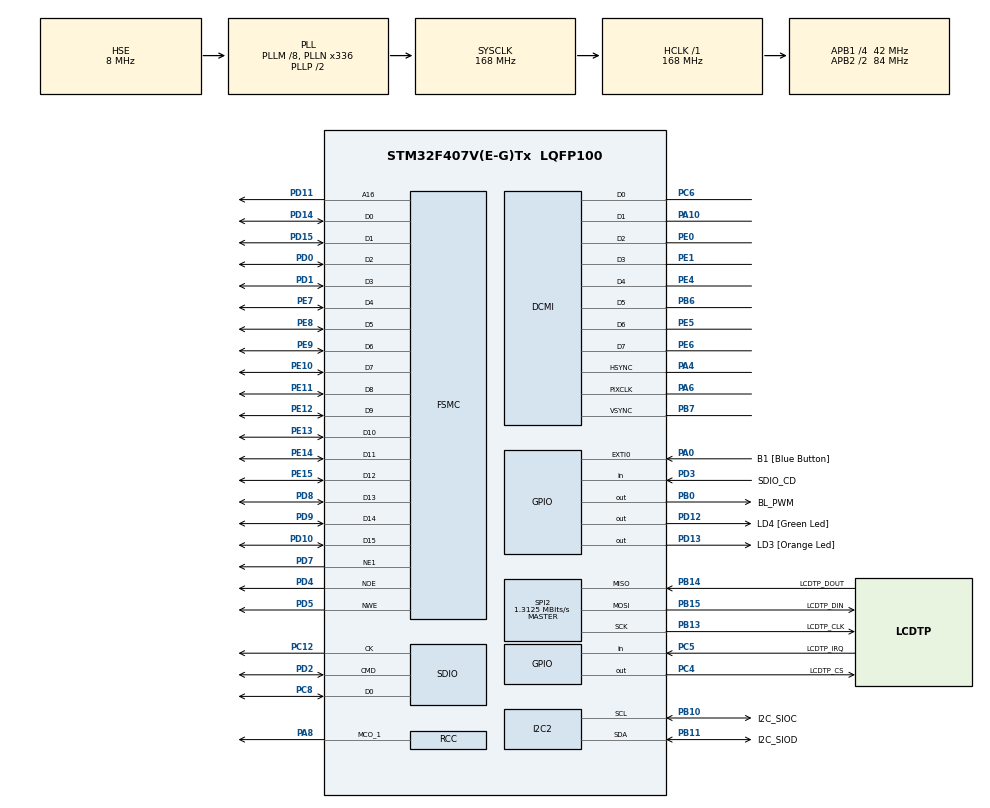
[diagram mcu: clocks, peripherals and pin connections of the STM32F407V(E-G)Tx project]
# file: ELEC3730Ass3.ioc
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DCMI.HSPolarity=DCMI_HSPOLARITY_HIGH
DCMI.VSPolarity=DCMI_VSPOLARITY_HIGH
Dma.DCMI.0.Direction=DMA_PERIPH_TO_MEMORY
Dma.DCMI.0.FIFOMode=DMA_FIFOMODE_ENABLE
Dma.DCMI.0.FIFOThreshold=DMA_FIFO_THRESHOLD_FULL
Dma.DCMI.0.Instance=DMA2_Stream1
Dma.DCMI.0.MemBurst=DMA_MBURST_SINGLE
Dma.DCMI.0.MemDataAlignment=DMA_MDATAALIGN_WORD
Dma.DCMI.0.MemInc=DMA_MINC_ENABLE
Dma.DCMI.0.Mode=DMA_CIRCULAR
Dma.DCMI.0.PeriphBurst=DMA_PBURST_SINGLE
Dma.DCMI.0.PeriphDataAlignment=DMA_PDATAALIGN_WORD
Dma.DCMI.0.PeriphInc=DMA_PINC_DISABLE
Dma.DCMI.0.Priority=DMA_PRIORITY_VERY_HIGH
Dma.MEMTOMEM.3.Direction=DMA_MEMORY_TO_MEMORY
Dma.MEMTOMEM.3.FIFOMode=DMA_FIFOMODE_ENABLE
Dma.MEMTOMEM.3.FIFOThreshold=DMA_FIFO_THRESHOLD_FULL
Dma.MEMTOMEM.3.Instance=DMA2_Stream0
Dma.MEMTOMEM.3.MemBurst=DMA_MBURST_SINGLE
Dma.MEMTOMEM.3.MemDataAlignment=DMA_MDATAALIGN_HALFWORD
Dma.MEMTOMEM.3.MemInc=DMA_MINC_DISABLE
Dma.MEMTOMEM.3.Mode=DMA_NORMAL
Dma.MEMTOMEM.3.PeriphBurst=DMA_PBURST_SINGLE
Dma.MEMTOMEM.3.PeriphDataAlignment=DMA_PDATAALIGN_HALFWORD
Dma.MEMTOMEM.3.PeriphInc=DMA_PINC_ENABLE
Dma.MEMTOMEM.3.Priority=DMA_PRIORITY_HIGH
Dma.Request0=DCMI
Dma.Request1=SDIO_RX
Dma.Request2=SDIO_TX
Dma.Request3=MEMTOMEM
Dma.SDIO_RX.1.Direction=DMA_PERIPH_TO_MEMORY
Dma.SDIO_RX.1.FIFOMode=DMA_FIFOMODE_ENABLE
Dma.SDIO_RX.1.FIFOThreshold=DMA_FIFO_THRESHOLD_FULL
Dma.SDIO_RX.1.Instance=DMA2_Stream3
Dma.SDIO_RX.1.MemBurst=DMA_MBURST_INC4
Dma.SDIO_RX.1.MemDataAlignment=DMA_MDATAALIGN_WORD
Dma.SDIO_RX.1.MemInc=DMA_MINC_ENABLE
Dma.SDIO_RX.1.Mode=DMA_PFCTRL
Dma.SDIO_RX.1.PeriphBurst=DMA_PBURST_INC4
Dma.SDIO_RX.1.PeriphDataAlignment=DMA_PDATAALIGN_WORD
Dma.SDIO_RX.1.PeriphInc=DMA_PINC_DISABLE
Dma.SDIO_RX.1.Priority=DMA_PRIORITY_VERY_HIGH
Dma.SDIO_TX.2.Direction=DMA_MEMORY_TO_PERIPH
Dma.SDIO_TX.2.FIFOMode=DMA_FIFOMODE_ENABLE
Dma.SDIO_TX.2.FIFOThreshold=DMA_FIFO_THRESHOLD_FULL
Dma.SDIO_TX.2.Instance=DMA2_Stream6
Dma.SDIO_TX.2.MemBurst=DMA_MBURST_INC4
Dma.SDIO_TX.2.MemDataAlignment=DMA_MDATAALIGN_WORD
Dma.SDIO_TX.2.MemInc=DMA_MINC_ENABLE
Dma.SDIO_TX.2.Mode=DMA_PFCTRL
Dma.SDIO_TX.2.PeriphBurst=DMA_PBURST_INC4
Dma.SDIO_TX.2.PeriphDataAlignment=DMA_PDATAALIGN_WORD
Dma.SDIO_TX.2.PeriphInc=DMA_PINC_DISABLE
Dma.SDIO_TX.2.Priority=DMA_PRIORITY_VERY_HIGH
FATFS.BSP.number=1
FATFS.USE_DMA_CODE_SD=1
FATFS._USE_LFN=2
FATFS0.BSP.STBoard=false
FATFS0.BSP.api=Unknown
FATFS0.BSP.instance=PD3
FATFS0.BSP.ip=GPIO
FATFS0.BSP.mode=Input
FATFS0.BSP.name=Detect_SDIO
FATFS0.BSP.solution=PD3
FREERTOS.BinarySemaphores01=startSem,Dynamic,NULL
FREERTOS.Mutexes01=lcdMutex,Dynamic,NULL;sdMutex,Dynamic,NULL
FREERTOS.Queues01=stateQueue,16,uint16_t,0,Dynamic,NULL,NULL;renderQueue,16,uint16_t,0,Dynamic,NULL,NULL;keypadQueue,4,uint16_t,0,Dynamic,NULL,NULL;fileSystemQueue,16,uint16_t,0,Dynamic,NULL,NULL
FREERTOS.Tasks01=defaultTask,0,128,StartDefaultTask,As weak,NULL,Dynamic,NULL,NULL;controlTask,0,128,StartControlTask,As weak,NULL,Dynamic,NULL,NULL;lcdTask,0,128,StartLCDTask,As weak,NULL,Dynamic,NULL,NULL;touchPanelTask,0,128,StartTouchPanelTask,As weak,NULL,Dynamic,NULL,NULL;keypadTask,0,128,StartKeypadTask,As weak,NULL,Dynamic,NULL,NULL;fileSystemTask,0,128,StartFileSystemTask,As weak,NULL,Dynamic,NULL,NULL;cameraTask,0,128,StartCameraTask,As weak,NULL,Dynamic,NULL,NULL
FREERTOS.Timers01=messageTimer,MessageTimerCallback,osTimerOnce,As weak,NULL,Dynamic,NULL
FREERTOS.configUSE_TIMERS=1
FSMC.AddressSetupTime1=4
FSMC.BusTurnAroundDuration1=0
FSMC.DataSetupTime1=40
Mcu.Family=STM32F4
Mcu.Name=STM32F407V(E-G)Tx
Mcu.Package=LQFP100
NVIC.DCMI_IRQn=true\:5\:0\:false\:false\:true\:true\:true\:true\:true
NVIC.DMA2_Stream1_IRQn=true\:5\:0\:false\:false\:true\:true\:false\:true\:true
NVIC.DMA2_Stream3_IRQn=true\:5\:0\:false\:false\:true\:true\:false\:true\:true
NVIC.DMA2_Stream6_IRQn=true\:5\:0\:false\:false\:true\:true\:false\:true\:true
NVIC.PriorityGroup=NVIC_PRIORITYGROUP_4
NVIC.SDIO_IRQn=true\:5\:0\:false\:false\:true\:true\:true\:true\:true
NVIC.SPI2_IRQn=true\:5\:0\:false\:false\:true\:true\:true\:true\:true
NVIC.TIM6_DAC_IRQn=true\:15\:0\:false\:false\:true\:false\:false\:true\:true
NVIC.TimeBase=TIM6_DAC_IRQn
NVIC.TimeBaseIP=TIM6
PA0-WKUP.GPIO_Label=B1 [Blue Button]
PA0-WKUP.GPIO_ModeDefaultEXTI=GPIO_MODE_EVT_RISING
PA0-WKUP.GPIO_PuPd=GPIO_NOPULL
PA0-WKUP.Signal=GPXTI0
PA10.Mode=Slave_8_bits_External_Synchro
PA10.Signal=DCMI_D1
PA4.Mode=Slave_8_bits_External_Synchro
PA4.Signal=DCMI_HSYNC
PA6.Mode=Slave_8_bits_External_Synchro
PA6.Signal=DCMI_PIXCLK
PA8.Mode=Clock-out-1
PA8.Signal=RCC_MCO_1
PB0.GPIO_Label=BL_PWM
PB0.Signal=GPIO_Output
PB10.GPIO_Label=I2C_SIOC
PB10.GPIO_Pu=GPIO_PULLUP
PB10.Mode=I2C
PB10.Signal=I2C2_SCL
PB11.GPIO_Label=I2C_SIOD
PB11.GPIO_Pu=GPIO_PULLUP
PB11.Mode=I2C
PB11.Signal=I2C2_SDA
PB13.GPIO_Label=LCDTP_CLK
PB13.Mode=Full_Duplex_Master
PB13.Signal=SPI2_SCK
PB14.GPIO_Label=LCDTP_DOUT
PB14.Mode=Full_Duplex_Master
PB14.Signal=SPI2_MISO
PB15.GPIO_Label=LCDTP_DIN
PB15.Mode=Full_Duplex_Master
PB15.Signal=SPI2_MOSI
PB6.Mode=Slave_8_bits_External_Synchro
PB6.Signal=DCMI_D5
PB7.Mode=Slave_8_bits_External_Synchro
PB7.Signal=DCMI_VSYNC
PC10.Signal=SDIO_D2
PC11.Signal=SDIO_D3
PC12.Mode=SD_1_bit
PC12.Signal=SDIO_CK
PC4.GPIO_Label=LCDTP_CS
PC4.GPIO_PuPd=GPIO_PULLDOWN
PC4.Signal=GPIO_Output
PC5.GPIO_Label=LCDTP_IRQ
PC5.Signal=GPIO_Input
PC6.Mode=Slave_8_bits_External_Synchro
PC6.Signal=DCMI_D0
PC8.Mode=SD_1_bit
PC8.Signal=SDIO_D0
PD0.Mode=16b-d1
PD0.Signal=FSMC_D2
PD1.Mode=16b-d1
PD1.Signal=FSMC_D3
PD10.Mode=16b-d1
PD10.Signal=FSMC_D15
PD11.Mode=A16_1
PD11.Signal=FSMC_A16
PD12.GPIO_Label=LD4 [Green Led]
PD12.GPIO_PuPd=GPIO_NOPULL
PD12.GPIO_Speed=GPIO_SPEED_FREQ_LOW
PD12.Signal=GPIO_Output
PD13.GPIO_Label=LD3 [Orange Led]
PD13.GPIO_PuPd=GPIO_NOPULL
PD13.GPIO_Speed=GPIO_SPEED_FREQ_LOW
PD13.Signal=GPIO_Output
PD14.Mode=16b-d1
PD14.Signal=FSMC_D0
PD15.Mode=16b-d1
PD15.Signal=FSMC_D1
PD2.Mode=SD_1_bit
PD2.Signal=SDIO_CMD
PD3.GPIO_Label=SDIO_CD
PD3.Signal=GPIO_Input
PD4.Mode=Lcd1
PD4.Signal=FSMC_NOE
PD5.Mode=Lcd1
PD5.Signal=FSMC_NWE
PD7.Mode=NorPsramChipSelect1_1
PD7.Signal=FSMC_NE1
PD8.Mode=16b-d1
PD8.Signal=FSMC_D13
PD9.Mode=16b-d1
PD9.Signal=FSMC_D14
PE0.Mode=Slave_8_bits_External_Synchro
PE0.Signal=DCMI_D2
PE1.Mode=Slave_8_bits_External_Synchro
PE1.Signal=DCMI_D3
PE10.Mode=16b-d1
PE10.Signal=FSMC_D7
PE11.Mode=16b-d1
PE11.Signal=FSMC_D8
PE12.Mode=16b-d1
PE12.Signal=FSMC_D9
PE13.Mode=16b-d1
PE13.Signal=FSMC_D10
PE14.Mode=16b-d1
PE14.Signal=FSMC_D11
PE15.Mode=16b-d1
PE15.Signal=FSMC_D12
PE4.Mode=Slave_8_bits_External_Synchro
PE4.Signal=DCMI_D4
PE5.Mode=Slave_8_bits_External_Synchro
PE5.Signal=DCMI_D6
PE6.Mode=Slave_8_bits_External_Synchro
PE6.Signal=DCMI_D7
PE7.Mode=16b-d1
PE7.Signal=FSMC_D4
PE8.Mode=16b-d1
PE8.Signal=FSMC_D5
PE9.Mode=16b-d1
PE9.Signal=FSMC_D6
PH0-OSC_IN.GPIO_Label=PH0-OSC_IN
PH0-OSC_IN.Mode=HSE-External-Oscillator
PH0-OSC_IN.Signal=RCC_OSC_IN
PH1-OSC_OUT.GPIO_Label=PH1-OSC_OUT
PH1-OSC_OUT.Mode=HSE-External-Oscillator
PH1-OSC_OUT.Signal=RCC_OSC_OUT
ProjectManager.HeapSize=0x200
ProjectManager.StackSize=0x400
ProjectManager.TargetToolchain=STM32CubeIDE
RCC.48MHZClocksFreq_Value=48000000
RCC.AHBFreq_Value=168000000
RCC.APB1CLKDivider=RCC_HCLK_DIV4
RCC.APB1Freq_Value=42000000
RCC.APB1TimFreq_Value=84000000
RCC.APB2CLKDivider=RCC_HCLK_DIV2
RCC.APB2Freq_Value=84000000
RCC.APB2TimFreq_Value=168000000
RCC.CortexFreq_Value=168000000
RCC.HCLKFreq_Value=168000000
RCC.HSE_VALUE=8000000
RCC.HSI_VALUE=16000000
RCC.LSE_VALUE=32768
RCC.PLLM=8
RCC.PLLN=336
RCC.PLLQ=7
RCC.PLLSourceVirtual=RCC_PLLSOURCE_HSE
RCC.SYSCLKFreq_VALUE=168000000
RCC.SYSCLKSource=RCC_SYSCLKSOURCE_PLLCLK
RCC.VCOOutputFreq_Value=336000000
SPI2.BaudRatePrescaler=SPI_BAUDRATEPRESCALER_32
SPI2.CalculateBaudRate=1.3125 MBits/s
SPI2.Direction=SPI_DIRECTION_2LINES
SPI2.Mode=SPI_MODE_MASTER
SPI2.VirtualType=VM_MASTER
VP_FATFS_VS_SDIO.Mode=SDIO
VP_FREERTOS_VS_CMSIS_V1.Mode=CMSIS_V1
VP_SYS_VS_tim6.Mode=TIM6
board=STM32F407G-DISC1

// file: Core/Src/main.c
/* USER CODE BEGIN Header */
/**
  ******************************************************************************
  * @file           : main.c
  * @brief          : Main program body
  ******************************************************************************
  * @attention
  *
  * Copyright (c) 2023 STMicroelectronics.
  * All rights reserved.
  *
  * This software is licensed under terms that can be found in the LICENSE file
  * in the root directory of this software component.
  * If no LICENSE file comes with this software, it is provided AS-IS.
  *
  ******************************************************************************
  */
/* USER CODE END Header */
#include "main.h"
#include "cmsis_os.h"
#include "dcmi.h"
#include "dma.h"
#include "fatfs.h"
#include "i2c.h"
#include "sdio.h"
#include "spi.h"
#include "gpio.h"
#include "fsmc.h"

/* USER CODE BEGIN Includes */
#include "openx07v_c_lcd.h"
#include "dcmi_ov7670.h"
#include "touch_panel.h"
/* USER CODE END Includes */

void SystemClock_Config(void);
void MX_FREERTOS_Init(void);
/* USER CODE BEGIN PFP */
extern void initialise_monitor_handles(void);
/* USER CODE END PFP */

int main(void)
{
  /* USER CODE BEGIN 1 */
	initialise_monitor_handles();
  /* USER CODE END 1 */

  /* MCU Configuration--------------------------------------------------------*/

  /* Reset of all peripherals, Initializes the Flash interface and the Systick. */
  HAL_Init();

  /* Configure the system clock */
  SystemClock_Config();

  /* Initialize all configured peripherals */
  MX_GPIO_Init();
  MX_DMA_Init();
  MX_FSMC_Init();
  MX_DCMI_Init();
  MX_I2C2_Init();
  MX_SDIO_SD_Init();
  MX_SPI2_Init();
  MX_FATFS_Init();

  /* Call init function for freertos objects (in freertos.c) */
  MX_FREERTOS_Init();

  /* Start scheduler */
  osKernelStart();
  /* We should never get here as control is now taken by the scheduler */
  /* Infinite loop */
  while (1)
  {

  }
}

void SystemClock_Config(void)
{
  RCC_OscInitTypeDef RCC_OscInitStruct = {0};
  RCC_ClkInitTypeDef RCC_ClkInitStruct = {0};

  /** Configure the main internal regulator output voltage
  */
  __HAL_RCC_PWR_CLK_ENABLE();
  __HAL_PWR_VOLTAGESCALING_CONFIG(PWR_REGULATOR_VOLTAGE_SCALE1);

  /** Initializes the RCC Oscillators according to the specified parameters
  * in the RCC_OscInitTypeDef structure.
  */
  RCC_OscInitStruct.OscillatorType = RCC_OSCILLATORTYPE_HSI|RCC_OSCILLATORTYPE_HSE;
  RCC_OscInitStruct.HSEState = RCC_HSE_ON;
  RCC_OscInitStruct.HSIState = RCC_HSI_ON;
  RCC_OscInitStruct.HSICalibrationValue = RCC_HSICALIBRATION_DEFAULT;
  RCC_OscInitStruct.PLL.PLLState = RCC_PLL_ON;
  RCC_OscInitStruct.PLL.PLLSource = RCC_PLLSOURCE_HSE;
  RCC_OscInitStruct.PLL.PLLM = 8;
  RCC_OscInitStruct.PLL.PLLN = 336;
  RCC_OscInitStruct.PLL.PLLP = RCC_PLLP_DIV2;
  RCC_OscInitStruct.PLL.PLLQ = 7;
  if (HAL_RCC_OscConfig(&RCC_OscInitStruct) != HAL_OK)
  {
    Error_Handler();
  }

  /** Initializes the CPU, AHB and APB buses clocks
  */
  RCC_ClkInitStruct.ClockType = RCC_CLOCKTYPE_HCLK|RCC_CLOCKTYPE_SYSCLK
                              |RCC_CLOCKTYPE_PCLK1|RCC_CLOCKTYPE_PCLK2;
  RCC_ClkInitStruct.SYSCLKSource = RCC_SYSCLKSOURCE_PLLCLK;
  RCC_ClkInitStruct.AHBCLKDivider = RCC_SYSCLK_DIV1;
  RCC_ClkInitStruct.APB1CLKDivider = RCC_HCLK_DIV4;
  RCC_ClkInitStruct.APB2CLKDivider = RCC_HCLK_DIV2;

  if (HAL_RCC_ClockConfig(&RCC_ClkInitStruct, FLASH_LATENCY_5) != HAL_OK)
  {
    Error_Handler();
  }
  HAL_RCC_MCOConfig(RCC_MCO1, RCC_MCO1SOURCE_HSI, RCC_MCODIV_1);
}

void HAL_TIM_PeriodElapsedCallback(TIM_HandleTypeDef *htim)
{
  if (htim->Instance == TIM6) {
    HAL_IncTick();
  }
}

void Error_Handler(void)
{
  __disable_irq();
  while (1)
  {
  }
}

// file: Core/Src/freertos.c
/* USER CODE BEGIN Header */
/**
  ******************************************************************************
  * File Name          : freertos.c
  * Description        : Code for freertos applications
  ******************************************************************************
  * @attention
  *
  * Copyright (c) 2023 STMicroelectronics.
  * All rights reserved.
  *
  * This software is licensed under terms that can be found in the LICENSE file
  * in the root directory of this software component.
  * If no LICENSE file comes with this software, it is provided AS-IS.
  *
  ******************************************************************************
  */
/* USER CODE END Header */

#include "FreeRTOS.h"
#include "task.h"
#include "main.h"
#include "cmsis_os.h"

osThreadId defaultTaskHandle;
osThreadId controlTaskHandle;
osThreadId lcdTaskHandle;
osThreadId touchPanelTaskHandle;
osThreadId keypadTaskHandle;
osThreadId fileSystemTaskHandle;
osThreadId cameraTaskHandle;
osMessageQId stateQueueHandle;
osMessageQId renderQueueHandle;
osMessageQId keypadQueueHandle;
osMessageQId fileSystemQueueHandle;
osTimerId messageTimerHandle;
osMutexId lcdMutexHandle;
osMutexId sdMutexHandle;
osSemaphoreId startSemHandle;

void StartDefaultTask(void const * argument);
void StartControlTask(void const * argument);
void StartLCDTask(void const * argument);
void StartTouchPanelTask(void const * argument);
void StartKeypadTask(void const * argument);
void StartFileSystemTask(void const * argument);
void StartCameraTask(void const * argument);
void MessageTimerCallback(void const * argument);

void MX_FREERTOS_Init(void); /* (MISRA C 2004 rule 8.1) */

/* GetIdleTaskMemory prototype (linked to static allocation support) */
void vApplicationGetIdleTaskMemory( StaticTask_t **ppxIdleTaskTCBBuffer, StackType_t **ppxIdleTaskStackBuffer, uint32_t *pulIdleTaskStackSize );

/* GetTimerTaskMemory prototype (linked to static allocation support) */
void vApplicationGetTimerTaskMemory( StaticTask_t **ppxTimerTaskTCBBuffer, StackType_t **ppxTimerTaskStackBuffer, uint32_t *pulTimerTaskStackSize );

/* USER CODE BEGIN GET_IDLE_TASK_MEMORY */
static StaticTask_t xIdleTaskTCBBuffer;
static StackType_t xIdleStack[configMINIMAL_STACK_SIZE];

void vApplicationGetIdleTaskMemory( StaticTask_t **ppxIdleTaskTCBBuffer, StackType_t **ppxIdleTaskStackBuffer, uint32_t *pulIdleTaskStackSize )
{
  *ppxIdleTaskTCBBuffer = &xIdleTaskTCBBuffer;
  *ppxIdleTaskStackBuffer = &xIdleStack[0];
  *pulIdleTaskStackSize = configMINIMAL_STACK_SIZE;
  /* place for user code */
}
/* USER CODE END GET_IDLE_TASK_MEMORY */

/* USER CODE BEGIN GET_TIMER_TASK_MEMORY */
static StaticTask_t xTimerTaskTCBBuffer;
static StackType_t xTimerStack[configTIMER_TASK_STACK_DEPTH];

void vApplicationGetTimerTaskMemory( StaticTask_t **ppxTimerTaskTCBBuffer, StackType_t **ppxTimerTaskStackBuffer, uint32_t *pulTimerTaskStackSize )
{
  *ppxTimerTaskTCBBuffer = &xTimerTaskTCBBuffer;
  *ppxTimerTaskStackBuffer = &xTimerStack[0];
  *pulTimerTaskStackSize = configTIMER_TASK_STACK_DEPTH;
  /* place for user code */
}
/* USER CODE END GET_TIMER_TASK_MEMORY */

void MX_FREERTOS_Init(void) {
  /* Create the mutex(es) */
  /* definition and creation of lcdMutex */
  osMutexDef(lcdMutex);
  lcdMutexHandle = osMutexCreate(osMutex(lcdMutex));

  /* definition and creation of sdMutex */
  osMutexDef(sdMutex);
  sdMutexHandle = osMutexCreate(osMutex(sdMutex));

  /* Create the semaphores(s) */
  /* definition and creation of startSem */
  osSemaphoreDef(startSem);
  startSemHandle = osSemaphoreCreate(osSemaphore(startSem), 1);

  /* Create the timer(s) */
  /* definition and creation of messageTimer */
  osTimerDef(messageTimer, MessageTimerCallback);
  messageTimerHandle = osTimerCreate(osTimer(messageTimer), osTimerOnce, NULL);

  /* Create the queue(s) */
  /* definition and creation of stateQueue */
  osMessageQDef(stateQueue, 16, uint16_t);
  stateQueueHandle = osMessageCreate(osMessageQ(stateQueue), NULL);

  /* definition and creation of renderQueue */
  osMessageQDef(renderQueue, 16, uint16_t);
  renderQueueHandle = osMessageCreate(osMessageQ(renderQueue), NULL);

  /* definition and creation of keypadQueue */
  osMessageQDef(keypadQueue, 4, uint16_t);
  keypadQueueHandle = osMessageCreate(osMessageQ(keypadQueue), NULL);

  /* definition and creation of fileSystemQueue */
  osMessageQDef(fileSystemQueue, 16, uint16_t);
  fileSystemQueueHandle = osMessageCreate(osMessageQ(fileSystemQueue), NULL);

  /* Create the thread(s) */
  /* definition and creation of defaultTask */
  osThreadDef(defaultTask, StartDefaultTask, osPriorityNormal, 0, 128);
  defaultTaskHandle = osThreadCreate(osThread(defaultTask), NULL);

  /* definition and creation of controlTask */
  osThreadDef(controlTask, StartControlTask, osPriorityNormal, 0, 128);
  controlTaskHandle = osThreadCreate(osThread(controlTask), NULL);

  /* definition and creation of lcdTask */
  osThreadDef(lcdTask, StartLCDTask, osPriorityNormal, 0, 128);
  lcdTaskHandle = osThreadCreate(osThread(lcdTask), NULL);

  /* definition and creation of touchPanelTask */
  osThreadDef(touchPanelTask, StartTouchPanelTask, osPriorityNormal, 0, 128);
  touchPanelTaskHandle = osThreadCreate(osThread(touchPanelTask), NULL);

  /* definition and creation of keypadTask */
  osThreadDef(keypadTask, StartKeypadTask, osPriorityNormal, 0, 128);
  keypadTaskHandle = osThreadCreate(osThread(keypadTask), NULL);

  /* definition and creation of fileSystemTask */
  osThreadDef(fileSystemTask, StartFileSystemTask, osPriorityNormal, 0, 128);
  fileSystemTaskHandle = osThreadCreate(osThread(fileSystemTask), NULL);

  /* definition and creation of cameraTask */
  osThreadDef(cameraTask, StartCameraTask, osPriorityNormal, 0, 128);
  cameraTaskHandle = osThreadCreate(osThread(cameraTask), NULL);

}

__weak void StartDefaultTask(void const * argument)
{
  for(;;)
  {
    osDelay(1);
  }
}

__weak void StartControlTask(void const * argument)
{
  for(;;)
  {
    osDelay(1);
  }
}

__weak void StartLCDTask(void const * argument)
{
  for(;;)
  {
    osDelay(1);
  }
}

__weak void StartTouchPanelTask(void const * argument)
{
  for(;;)
  {
    osDelay(1);
  }
}

__weak void StartKeypadTask(void const * argument)
{
  for(;;)
  {
    osDelay(1);
  }
}

__weak void StartFileSystemTask(void const * argument)
{
  for(;;)
  {
    osDelay(1);
  }
}

__weak void StartCameraTask(void const * argument)
{
  for(;;)
  {
    osDelay(1);
  }
}

/* MessageTimerCallback function */
__weak void MessageTimerCallback(void const * argument)
{
}
